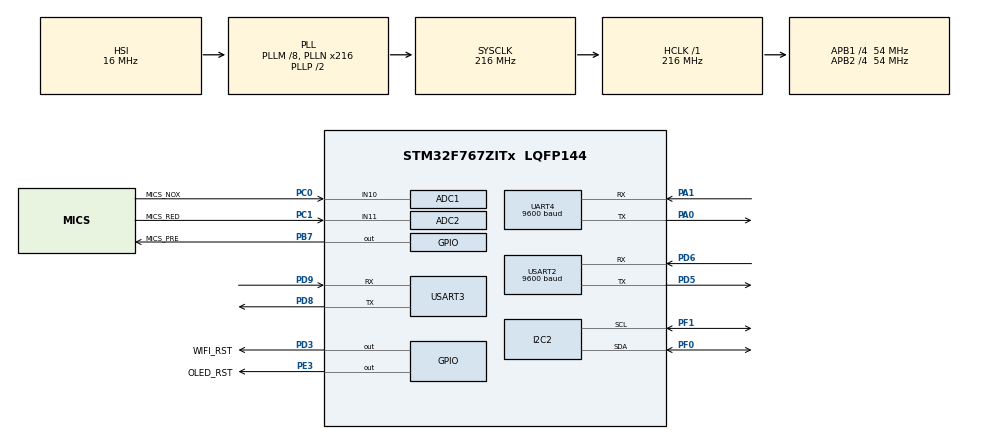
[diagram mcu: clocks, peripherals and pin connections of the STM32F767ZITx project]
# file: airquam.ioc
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ADC1.Channel-0\#ChannelRegularConversion=ADC_CHANNEL_10
ADC1.ClockPrescaler=ADC_CLOCK_SYNC_PCLK_DIV4
ADC1.NbrOfConversionFlag=1
ADC1.Rank-0\#ChannelRegularConversion=1
ADC1.SamplingTime-0\#ChannelRegularConversion=ADC_SAMPLETIME_3CYCLES
ADC1.master=1
ADC2.Channel-0\#ChannelRegularConversion=ADC_CHANNEL_11
ADC2.ClockPrescaler=ADC_CLOCK_SYNC_PCLK_DIV4
ADC2.NbrOfConversionFlag=1
ADC2.Rank-0\#ChannelRegularConversion=1
ADC2.SamplingTime-0\#ChannelRegularConversion=ADC_SAMPLETIME_3CYCLES
FREERTOS.Tasks01=iddleTask,-3,128,StartDefaultTask,Default,NULL,Dynamic,NULL,NULL;taskWifi,0,1024,vWifi_taskFunction,As external,NULL,Dynamic,NULL,NULL;taskGps,0,1024,vGps_taskFunction,As external,NULL,Dynamic,NULL,NULL;taskAirquam,0,1024,vAirquam_taskFunction,As external,NULL,Dynamic,NULL,NULL
I2C2.Timing=0x20404768
Mcu.Family=STM32F7
Mcu.Name=STM32F767ZITx
Mcu.Package=LQFP144
NVIC.PriorityGroup=NVIC_PRIORITYGROUP_4
NVIC.TIM1_UP_TIM10_IRQn=true\:0\:0\:false\:false\:true\:false\:false\:true
NVIC.TIM2_IRQn=true\:6\:0\:true\:false\:true\:true\:true\:true
NVIC.TimeBase=TIM1_UP_TIM10_IRQn
NVIC.TimeBaseIP=TIM1
NVIC.UART4_IRQn=true\:5\:0\:false\:false\:true\:true\:true\:true
NVIC.USART2_IRQn=true\:5\:0\:false\:false\:true\:true\:true\:true
NVIC.USART3_IRQn=true\:5\:0\:false\:false\:true\:true\:true\:true
PA0/WKUP.Mode=Asynchronous
PA0/WKUP.Signal=UART4_TX
PA1.Mode=Asynchronous
PA1.Signal=UART4_RX
PA13.Mode=Serial_Wire
PA13.Signal=SYS_JTMS-SWDIO
PA14.Mode=Serial_Wire
PA14.Signal=SYS_JTCK-SWCLK
PB7.GPIO_Label=MICS_PRE
PB7.Signal=GPIO_Output
PC0.GPIO_Label=MICS_NOX
PC0.Signal=ADCx_IN10
PC1.GPIO_Label=MICS_RED
PC1.Signal=ADCx_IN11
PC14/OSC32_IN.Mode=LSE-External-Oscillator
PC14/OSC32_IN.Signal=RCC_OSC32_IN
PC15/OSC32_OUT.Mode=LSE-External-Oscillator
PC15/OSC32_OUT.Signal=RCC_OSC32_OUT
PD3.GPIO_Label=WIFI_RST
PD3.GPIO_PuPd=GPIO_PULLUP
PD3.Signal=GPIO_Output
PD5.Mode=Asynchronous
PD5.Signal=USART2_TX
PD6.Mode=Asynchronous
PD6.Signal=USART2_RX
PD8.Mode=Asynchronous
PD8.Signal=USART3_TX
PD9.Mode=Asynchronous
PD9.Signal=USART3_RX
PE3.GPIO_Label=OLED_RST
PE3.Signal=GPIO_Output
PF0.Mode=I2C
PF0.Signal=I2C2_SDA
PF1.Mode=I2C
PF1.Signal=I2C2_SCL
ProjectManager.HeapSize=0x200
ProjectManager.StackSize=0x400
ProjectManager.TargetToolchain=MDK-ARM V5
RCC.48MHZClocksFreq_Value=24000000
RCC.AHBFreq_Value=216000000
RCC.APB1CLKDivider=RCC_HCLK_DIV4
RCC.APB1Freq_Value=54000000
RCC.APB1TimFreq_Value=108000000
RCC.APB2CLKDivider=RCC_HCLK_DIV4
RCC.APB2Freq_Value=54000000
RCC.APB2TimFreq_Value=108000000
RCC.CortexFreq_Value=216000000
RCC.HCLKFreq_Value=216000000
RCC.HSE_VALUE=16000000
RCC.HSI_VALUE=16000000
RCC.PLLM=8
RCC.PLLMUL=RCC_PLL_MUL9
RCC.PLLN=216
RCC.PRESCALERUSB=RCC_USBCLKSOURCE_PLL_DIV1_5
RCC.RTCClockSelection=RCC_RTCCLKSOURCE_LSE
RCC.SYSCLKFreq_VALUE=216000000
RCC.SYSCLKSource=RCC_SYSCLKSOURCE_PLLCLK
RCC.SYSCLKSourceVirtual=RCC_SYSCLKSOURCE_PLLCLK
RCC.USBFreq_Value=216000000
RCC.VCOOutputFreq_Value=432000000
SH.ADCx_IN10.0=ADC1_IN10,IN10
SH.ADCx_IN11.0=ADC2_IN11,IN11
TIM2.Period=100000
TIM2.Prescaler=1080
UART4.BaudRate=9600
USART2.BaudRate=9600
USART2.VirtualMode-Asynchronous=VM_ASYNC
USART3.VirtualMode-Asynchronous=VM_ASYNC
VP_FREERTOS_VS_CMSIS_V1.Mode=CMSIS_V1
VP_RTC_VS_RTC_Activate.Mode=RTC_Enabled
VP_SYS_VS_tim1.Mode=TIM1
VP_TIM2_VS_ClockSourceINT.Mode=Internal
board=NUCLEO-F767ZI

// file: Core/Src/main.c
/* USER CODE BEGIN Header */
/**
  ******************************************************************************
  * @file           : main.c
  * @brief          : Main program body
  ******************************************************************************
  * @attention
  *
  * <h2><center>&copy; Copyright (c) 2019 STMicroelectronics.
  * All rights reserved.</center></h2>
  *
  * This software component is licensed by ST under Ultimate Liberty license
  * SLA0044, the "License"; You may not use this file except in compliance with
  * the License. You may obtain a copy of the License at:
  *                             www.st.com/SLA0044
  *
  ******************************************************************************
  */
/* USER CODE END Header */
#include "airquam.h"
#include "main.h"
#include "cmsis_os.h"
#include "adc.h"
#include "i2c.h"
#include "rtc.h"
#include "tim.h"
#include "usart.h"
#include "gpio.h"

/* USER CODE BEGIN Includes */
#include "airquam.h"
/* USER CODE END Includes */

void SystemClock_Config(void);
void MX_FREERTOS_Init(void);

int main(void)
{

  /* MCU Configuration--------------------------------------------------------*/

  /* Reset of all peripherals, Initializes the Flash interface and the Systick. */
  HAL_Init();

  /* Configure the system clock */
  SystemClock_Config();

  /* Initialize all configured peripherals */
  MX_GPIO_Init();
  MX_ADC1_Init();
  MX_ADC2_Init();
  MX_I2C2_Init();
  MX_RTC_Init();
  MX_UART4_Init();
  MX_USART2_UART_Init();
  MX_USART3_UART_Init();
  MX_TIM2_Init();
  /* USER CODE BEGIN 2 */

	printf("hello");
	airquam_init();
  /* USER CODE END 2 */

  /* Call init function for freertos objects (in freertos.c) */
  MX_FREERTOS_Init();

  /* Start scheduler */
  osKernelStart();

  /* We should never get here as control is now taken by the scheduler */

  /* Infinite loop */
  while (1)
  {

  }
}

void SystemClock_Config(void)
{
  RCC_OscInitTypeDef RCC_OscInitStruct = {0};
  RCC_ClkInitTypeDef RCC_ClkInitStruct = {0};
  RCC_PeriphCLKInitTypeDef PeriphClkInitStruct = {0};

  /** Configure LSE Drive Capability
  */
  HAL_PWR_EnableBkUpAccess();
  __HAL_RCC_LSEDRIVE_CONFIG(RCC_LSEDRIVE_LOW);
  /** Configure the main internal regulator output voltage
  */
  __HAL_RCC_PWR_CLK_ENABLE();
  __HAL_PWR_VOLTAGESCALING_CONFIG(PWR_REGULATOR_VOLTAGE_SCALE1);
  /** Initializes the CPU, AHB and APB busses clocks
  */
  RCC_OscInitStruct.OscillatorType = RCC_OSCILLATORTYPE_HSI|RCC_OSCILLATORTYPE_LSE;
  RCC_OscInitStruct.LSEState = RCC_LSE_ON;
  RCC_OscInitStruct.HSIState = RCC_HSI_ON;
  RCC_OscInitStruct.HSICalibrationValue = RCC_HSICALIBRATION_DEFAULT;
  RCC_OscInitStruct.PLL.PLLState = RCC_PLL_ON;
  RCC_OscInitStruct.PLL.PLLSource = RCC_PLLSOURCE_HSI;
  RCC_OscInitStruct.PLL.PLLM = 8;
  RCC_OscInitStruct.PLL.PLLN = 216;
  RCC_OscInitStruct.PLL.PLLP = RCC_PLLP_DIV2;
  RCC_OscInitStruct.PLL.PLLQ = 2;
  if (HAL_RCC_OscConfig(&RCC_OscInitStruct) != HAL_OK)
  {
    Error_Handler();
  }
  /** Activate the Over-Drive mode
  */
  if (HAL_PWREx_EnableOverDrive() != HAL_OK)
  {
    Error_Handler();
  }
  /** Initializes the CPU, AHB and APB busses clocks
  */
  RCC_ClkInitStruct.ClockType = RCC_CLOCKTYPE_HCLK|RCC_CLOCKTYPE_SYSCLK
                              |RCC_CLOCKTYPE_PCLK1|RCC_CLOCKTYPE_PCLK2;
  RCC_ClkInitStruct.SYSCLKSource = RCC_SYSCLKSOURCE_PLLCLK;
  RCC_ClkInitStruct.AHBCLKDivider = RCC_SYSCLK_DIV1;
  RCC_ClkInitStruct.APB1CLKDivider = RCC_HCLK_DIV4;
  RCC_ClkInitStruct.APB2CLKDivider = RCC_HCLK_DIV4;

  if (HAL_RCC_ClockConfig(&RCC_ClkInitStruct, FLASH_LATENCY_7) != HAL_OK)
  {
    Error_Handler();
  }
  PeriphClkInitStruct.PeriphClockSelection = RCC_PERIPHCLK_RTC|RCC_PERIPHCLK_USART2
                              |RCC_PERIPHCLK_USART3|RCC_PERIPHCLK_UART4
                              |RCC_PERIPHCLK_I2C2;
  PeriphClkInitStruct.RTCClockSelection = RCC_RTCCLKSOURCE_LSE;
  PeriphClkInitStruct.Usart2ClockSelection = RCC_USART2CLKSOURCE_PCLK1;
  PeriphClkInitStruct.Usart3ClockSelection = RCC_USART3CLKSOURCE_PCLK1;
  PeriphClkInitStruct.Uart4ClockSelection = RCC_UART4CLKSOURCE_PCLK1;
  PeriphClkInitStruct.I2c2ClockSelection = RCC_I2C2CLKSOURCE_PCLK1;
  if (HAL_RCCEx_PeriphCLKConfig(&PeriphClkInitStruct) != HAL_OK)
  {
    Error_Handler();
  }
}

void HAL_TIM_PeriodElapsedCallback(TIM_HandleTypeDef *htim)
{
  if (htim->Instance == TIM1) {
    HAL_IncTick();
  }
  /* USER CODE BEGIN Callback 1 */
  if (htim->Instance == PERIODIC_TIMER_HANDLER.Instance) {
		airquam_CallBack();
  }
  /* USER CODE END Callback 1 */
}

void Error_Handler(void)
{
}

/************************ (C) COPYRIGHT STMicroelectronics *****END OF FILE****/

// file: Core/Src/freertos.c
/* USER CODE BEGIN Header */
/**
  ******************************************************************************
  * File Name          : freertos.c
  * Description        : Code for freertos applications
  ******************************************************************************
  * @attention
  *
  * <h2><center>&copy; Copyright (c) 2019 STMicroelectronics.
  * All rights reserved.</center></h2>
  *
  * This software component is licensed by ST under Ultimate Liberty license
  * SLA0044, the "License"; You may not use this file except in compliance with
  * the License. You may obtain a copy of the License at:
  *                             www.st.com/SLA0044
  *
  ******************************************************************************
  */
/* USER CODE END Header */

#include "FreeRTOS.h"
#include "task.h"
#include "main.h"
#include "cmsis_os.h"

/* USER CODE BEGIN Includes */
#include "gps.h"
#include "gas.h"
#include "environment.h"
#include "airquam.h"
#include "stdio.h"
/* USER CODE END Includes */

osThreadId iddleTaskHandle;
osThreadId taskWifiHandle;
osThreadId taskGpsHandle;
osThreadId taskAirquamHandle;

void StartDefaultTask(void const * argument);
extern void vWifi_taskFunction(void const * argument);
extern void vGps_taskFunction(void const * argument);
extern void vAirquam_taskFunction(void const * argument);

void MX_FREERTOS_Init(void); /* (MISRA C 2004 rule 8.1) */

void MX_FREERTOS_Init(void) {

  /* Create the thread(s) */
  /* definition and creation of iddleTask */
  osThreadDef(iddleTask, StartDefaultTask, osPriorityIdle, 0, 128);
  iddleTaskHandle = osThreadCreate(osThread(iddleTask), NULL);

  /* definition and creation of taskWifi */
  osThreadDef(taskWifi, vWifi_taskFunction, osPriorityNormal, 0, 1024);
  taskWifiHandle = osThreadCreate(osThread(taskWifi), NULL);

  /* definition and creation of taskGps */
  osThreadDef(taskGps, vGps_taskFunction, osPriorityNormal, 0, 1024);
  taskGpsHandle = osThreadCreate(osThread(taskGps), NULL);

  /* definition and creation of taskAirquam */
  osThreadDef(taskAirquam, vAirquam_taskFunction, osPriorityNormal, 0, 1024);
  taskAirquamHandle = osThreadCreate(osThread(taskAirquam), NULL);

}

void StartDefaultTask(void const * argument)
{

  /* USER CODE BEGIN StartDefaultTask */
  /* Infinite loop */
  for(;;)
  {
    osDelay(1000);
  }
  /* USER CODE END StartDefaultTask */
}

/************************ (C) COPYRIGHT STMicroelectronics *****END OF FILE****/
